# APM32M35XX register map
File version: 1.0
Registers are 32-bit, read-write, reset 0x0 unless marked. A register's access mark holds for its fields unless they carry their own. Offsets are from the block's base; [hi:lo] are bit positions; {n}, {i} and the like mark numbered series.

## ADC — Analog-to-digital converter
Base 0x40012400
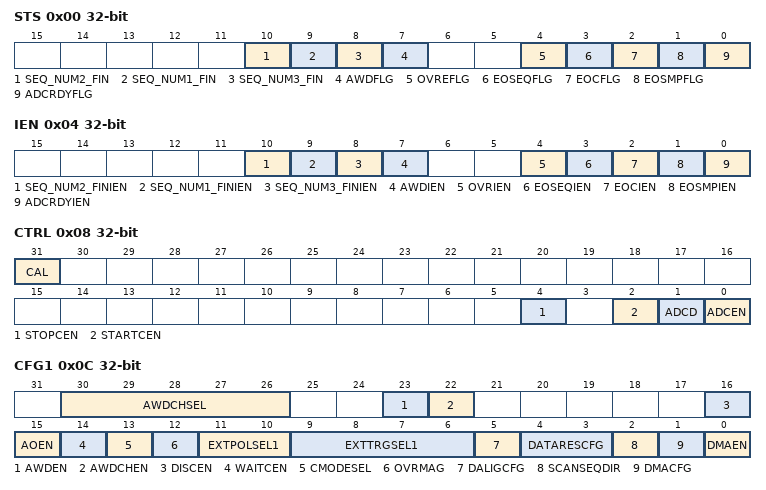
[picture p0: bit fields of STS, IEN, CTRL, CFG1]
0x00 STS — interrupt and status register
  [10] SEQ_NUM2_FIN — NUM2 of sequential section samping finish
  [9] SEQ_NUM1_FIN — NUM1 of sequential section samping finish
  [8] SEQ_NUM3_FIN — NUM3 of sequential section samping finish
  [7] AWDFLG — Analog watchdog flag
  [4] OVREFLG — ADC overrun flag
  [3] EOSEQFLG — End of sequence flag
  [2] EOCFLG — End of conversion flag
  [1] EOSMPFLG — End of sampling flag
  [0] ADCRDYFLG — ADC ready flag
0x04 IEN — interrupt enable register
  [10] SEQ_NUM2_FINIEN — NUM2 of sequential section samping finish interrupt enable
  [9] SEQ_NUM1_FINIEN — NUM1 of sequential section samping finish interrupt enable
  [8] SEQ_NUM3_FINIEN — NUM3 of sequential section samping finish interrupt enable
  [7] AWDIEN — Analog watchdog interrupt enable
  [4] OVRIEN — Overrun interrupt enable
  [3] EOSEQIEN — End of conversion sequence interrupt enable
  [2] EOCIEN — End of conversion interrupt enable
  [1] EOSMPIEN — End of sampling flag interrupt enable
  [0] ADCRDYIEN — ADC ready interrupt enable
0x08 CTRL — control register
  [31] CAL — ADC calibration
  [4] STOPCEN — ADC stop conversion command
  [2] STARTCEN — ADC start conversion command
  [1] ADCD — ADC disable command
  [0] ADCEN — ADC enable command
0x0C CFG1 — configuration register 1
  [30:26] AWDCHSEL — Analog watchdog channel selection
  [23] AWDEN — Analog watchdog enable
  [22] AWDCHEN — Enable the watchdog on a single channel or on all channels
  [16] DISCEN — Discontinuous mode
  [15] AOEN — Auto-off mode
  [14] WAITCEN — Auto-delayed conversion mode
  [13] CMODESEL — Single / continuous conversion mode
  [12] OVRMAG — Overrun management mode
  [11:10] EXTPOLSEL1 — External trigger enable and polarity selection
  [9:6] EXTTRGSEL1 — External trigger selection
  [5] DALIGCFG — Data alignment
  [4:3] DATARESCFG — Data resolution
  [2] SCANSEQDIR — Scan sequence direction
  [1] DMACFG — Direct memery access configuration
  [0] DMAEN — Direct memory access enable
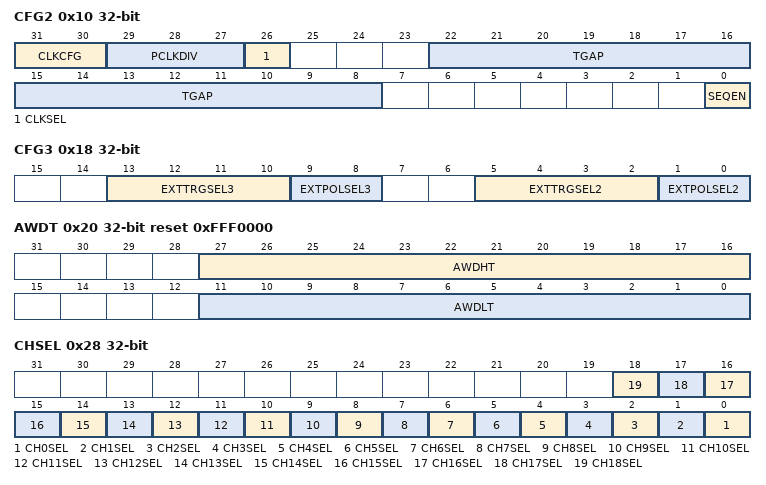
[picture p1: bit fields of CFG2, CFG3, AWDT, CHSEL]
0x10 CFG2 — configuration register 2
  [31:30] CLKCFG — ADC clock mode
  [29:27] PCLKDIV — PCLK division factor configure
  [26] CLKSEL — ADC conversion and analog clock select
  [22:8] TGAP — Time of the gap between CSS configure
  [0] SEQEN — Sequential section sampling enable
0x14 SMPTIM — sampling time register
  [2:0] SMPCYCSEL — Sampling time selection
0x18 CFG3 — configuration register 3
  [13:10] EXTTRGSEL3 — External trigger event select
  [9:8] EXTPOLSEL3 — External trigger enable and polarity select
  [5:2] EXTTRGSEL2 — External trigger event select
  [1:0] EXTPOLSEL2 — External trigger enable and polarity select
0x20 AWDT reset 0xFFF0000 — watchdog threshold register
  [27:16] AWDHT — Analog watchdog higher threshold
  [11:0] AWDLT — Analog watchdog lower threshold
0x28 CHSEL — channel selection register
  [n] CH{n}SEL (n=0..18) — Channel-{n} selection
0x40 DATA ro
  [15:0] CDATA — Converted data
{0x44+4i} DATA{i} (i=0..18) — Sequential Section Sampling Data register
  [15:0] ADC_DATA — Converted data
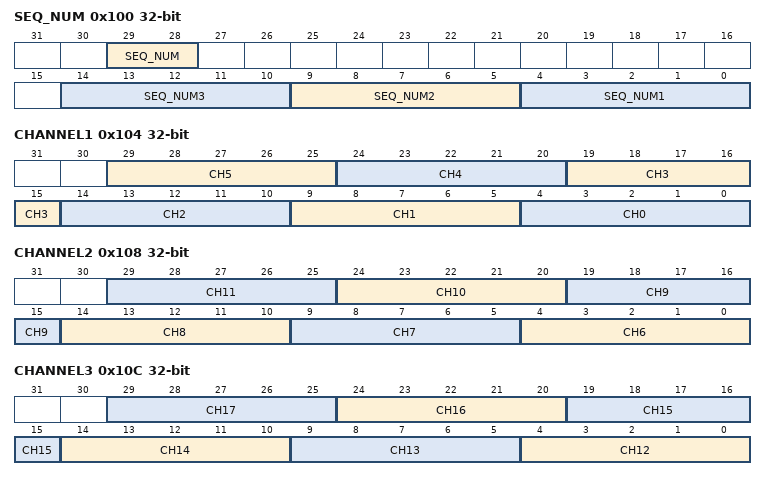
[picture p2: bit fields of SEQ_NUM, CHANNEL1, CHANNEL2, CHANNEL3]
0x100 SEQ_NUM — Sequential Section Sampling Control register
  [29:28] SEQ_NUM — Number of Sequencial Section
  [14:10] SEQ_NUM3 — Section 3 Transmission Time Setup
  [9:5] SEQ_NUM2 — Section 2 Transmission Time Setup
  [4:0] SEQ_NUM1 — Section 1 Transmission Time Setup
0x104 CHANNEL1
  [29:25] CH5 — Number of Channels Converted for The Sixth Time
  [24:20] CH4 — Number of Channels Converted for The Fifth Time
  [19:15] CH3 — Number of Channels Converted for The Forth Time
  [14:10] CH2 — Number of Channels Converted for The Third Time
  [9:5] CH1 — Number of Channels Converted for The Second Time
  [4:0] CH0 — Number of Channels Converted for The First Time
0x108 CHANNEL2
  [5n-26:5n-30] CH{n} (n=6..11) — Number of Channels Converted for The {n+1}th Time
0x10C CHANNEL3
  [5n-56:5n-60] CH{n} (n=12..17) — Number of Channels Converted for The {n+1}th Time
0x110 CHANNEL4
  [4:0] CH18 — Number of Channels Converted for The 19th Time
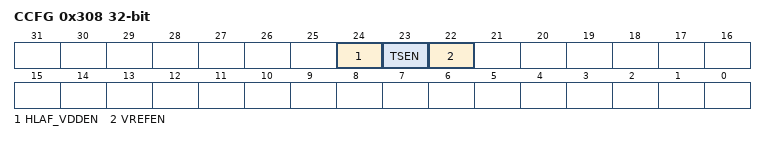
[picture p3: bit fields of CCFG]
0x308 CCFG — common configuration register
  [24] HLAF_VDDEN — 1/2 * VDD enable
  [23] TSEN — Temperature sensor enable
  [22] VREFEN — Temperature sensor and VREFINT enable
